# 602 register map
Vendor: bouffalolab; Series: WiFi BT
high-performance, 32-bit RV32IMAFC core
CPU: 602, little endian
Registers are 32-bit, read-write, reset 0x0 unless marked. A register's access mark holds for its fields unless they carry their own. Offsets are from the block's base; lines under a group give offsets from that group; [hi:lo] are bit positions; {n}, {i} and the like mark numbered series; 'fields as' and 'values as' point back to an identical list; <NAME> marks a mode.

## Memory map
0x02000000 CLINT size 0x10000 — Core Local Interruptor.
0x02800000 CLIC size 0x10000 — Core Local Interrupter controller.
0x40000000 GLB size 0x1000
0x40007000 eFuse size 0x1000 — eFuse Programmable Memory.

## CLINT — Core Local Interruptor.
Base 0x02000000
0x00 MSIP — Machine Software Interrupt Pending Register.
0x4000 MTIMECMP_LO — Machine Timer Compare Register Low.
0x4004 MTIMECMP_HI — Machine Timer Compare Register High.
0xBFF8 MTIME_LO — Machine Timer Register Low.
0xBFFC MTIME_HI — Machine Timer Register High.

## CLIC — Core Local Interrupter controller.
Base 0x02800000
{0x0+i} PENDING[{i}] (i=0..127) 8-bit — CLIC Interrupt Pending Registers.
  [0] PENDING
{0x400+i} ENABLE[{i}] (i=0..127) 8-bit — CLIC Interrupt enable Registers.
  [0] ENABLE
{0x800+i} INTCFG[{i}] (i=0..127) 8-bit — CLIC Interrupt config Registers.
  [7:3] INTCFG
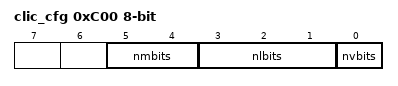
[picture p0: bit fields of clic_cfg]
0xC00 clic_cfg 8-bit
  [5:4] nmbits, [3:1] nlbits, [0] nvbits

## GLB
Base 0x40000000
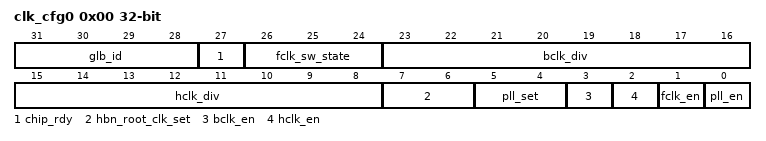
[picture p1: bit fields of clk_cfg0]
0x00 clk_cfg0
  [31:28] glb_id, [27] chip_rdy, [26:24] fclk_sw_state, [23:16] bclk_div, [15:8] hclk_div, [7:6] hbn_root_clk_set, [5:4] pll_set, [3] bclk_en, [2] hclk_en, [1] fclk_en, [0] pll_en

## eFuse — eFuse Programmable Memory.
Base 0x40007000
0x00 ef_cfg_0 ro
  [11:8] ef_boot_sel, [7] ef_cpu0_enc_en, [6] ef_cpu1_enc_en, [5:4] ef_sboot_en, [5:4] ef_sboot_en, [3:2] ef_sboot_sign_mode, [1:0] ef_sf_aes_mode
0x14 ef_wifi_mac_low ro
  [31:0] mac_addr1
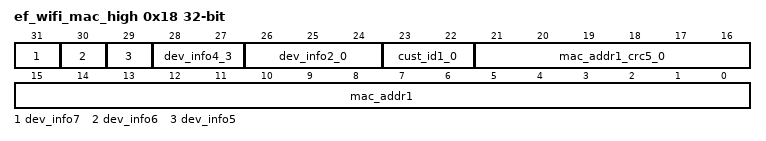
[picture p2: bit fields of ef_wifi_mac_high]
0x18 ef_wifi_mac_high ro
  [31] dev_info7, [30] dev_info6, [29] dev_info5, [28:27] dev_info4_3, [26:24] dev_info2_0, [23:22] cust_id1_0, [21:16] mac_addr1_crc5_0, [15:0] mac_addr1
